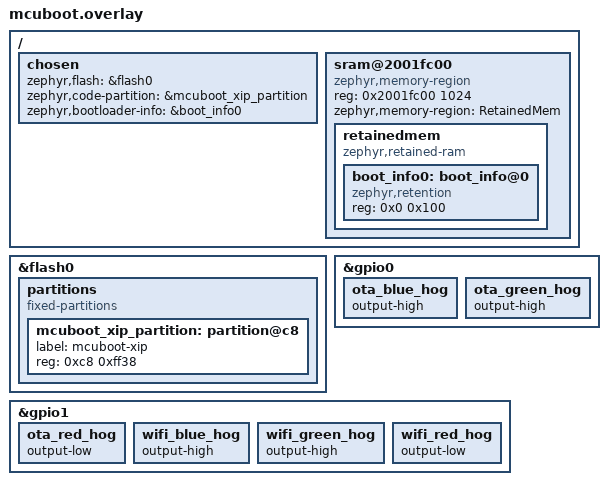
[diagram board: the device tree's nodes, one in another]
/ {
	chosen {
		zephyr,flash = &flash0;
		zephyr,code-partition = &mcuboot_xip_partition;
		zephyr,bootloader-info = &boot_info0;
	};

	sram@2001fc00 {
		compatible = "zephyr,memory-region", "mmio-sram";
		reg = <0x2001fc00 1024>;
		zephyr,memory-region = "RetainedMem";
		status = "okay";

		retainedmem {
			compatible = "zephyr,retained-ram";
			status = "okay";
			#address-cells = <1>;
			#size-cells = <1>;

			boot_info0: boot_info@0 {
				compatible = "zephyr,retention";
				status = "okay";
				reg = <0x0 0x100>;
			};
		};
	};
};

&flash0 {
	partitions {
		compatible = "fixed-partitions";
		#address-cells = <1>;
		#size-cells = <1>;

		mcuboot_xip_partition: partition@c8 {
			label = "mcuboot-xip";
			reg = <0xc8 0xff38>;
		};
	};
};

&gpio0 {
	ota_blue_hog {
		output-high;
	};

	ota_green_hog {
		/delete-property/ output-low;
		output-high;
	};
};

&gpio1 {
	ota_red_hog {
		output-low;
	};

	wifi_blue_hog {
		output-high;
	};

	wifi_green_hog {
		/delete-property/ output-low;
		output-high;
	};

	wifi_red_hog {
		output-low;
	};
};
